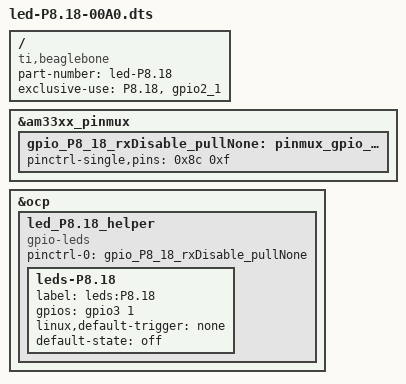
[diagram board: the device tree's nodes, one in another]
/*
* Easy gpio mux control of "P8.18" ("gpio2_1")
*/
/dts-v1/;
/plugin/;

/ {
	compatible = "ti,beaglebone", "ti,beaglebone-black";

	/* identification */
	part-number = "led-P8.18";
	/* version = "00A0"; */

	/* state the resources this cape uses */
	exclusive-use =
		/* the pin header uses */
		"P8.18",

		/* the hardware IP uses */
		"gpio2_1";
	
	
	/* rxDisable_pullNone state */
	fragment@0 {
		target = <&am33xx_pinmux>;
		__overlay__ {
			gpio_P8_18_rxDisable_pullNone: pinmux_gpio_P8.18_rxDisable_pullNone {
				pinctrl-single,pins = <
					0x8c 0xf
				>;
			};
		};
	};

	fragment@1 {
		target = <&ocp>;
		__overlay__ {
			led_P8.18_helper {
				compatible = "gpio-leds";
				pinctrl-names = "default";
				pinctrl-0 = <&gpio_P8_18_rxDisable_pullNone>;
				
				leds-P8.18 {
					label = "leds:P8.18";
					gpios = <&gpio3 1 0>;
					linux,default-trigger = "none";
					default-state = "off";
				};
			};
			
		};
	};

};
